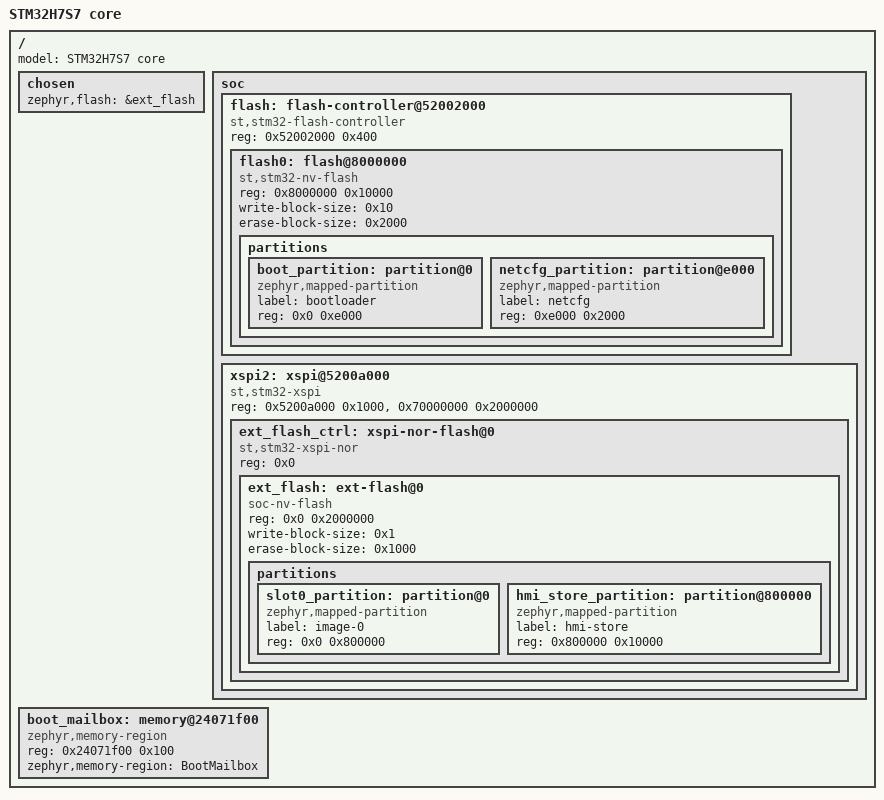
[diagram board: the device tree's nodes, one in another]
/dts-v1/;

/ {
	#address-cells = < 0x1 >;
	#size-cells = < 0x1 >;
	model = "STM32H7S7 core";
	chosen {
		zephyr,flash = &ext_flash;
	};
	soc {
		#address-cells = < 0x1 >;
		#size-cells = < 0x1 >;
		ranges;
		flash: flash-controller@52002000 {
			compatible = "st,stm32-flash-controller", "st,stm32h7rs-flash-controller";
			reg = < 0x52002000 0x400 >;
			#address-cells = < 0x1 >;
			#size-cells = < 0x1 >;
			flash0: flash@8000000 {
				compatible = "st,stm32-nv-flash", "soc-nv-flash";
				reg = < 0x8000000 0x10000 >;
				write-block-size = < 0x10 >;
				erase-block-size = < 0x2000 >;
				partitions {
					#address-cells = < 0x1 >;
					#size-cells = < 0x1 >;
					ranges;
					boot_partition: partition@0 {
						compatible = "zephyr,mapped-partition";
						label = "bootloader";
						reg = < 0x0 0xe000 >;
					};
					netcfg_partition: partition@e000 {
						compatible = "zephyr,mapped-partition";
						label = "netcfg";
						reg = < 0xe000 0x2000 >;
					};
				};
			};
		};
		xspi2: xspi@5200a000 {
			compatible = "st,stm32-xspi";
			reg = < 0x5200a000 0x1000 >, < 0x70000000 0x2000000 >;
			#address-cells = < 0x1 >;
			#size-cells = < 0x0 >;
			ext_flash_ctrl: xspi-nor-flash@0 {
				compatible = "st,stm32-xspi-nor";
				reg = < 0x0 >;
				#address-cells = < 0x1 >;
				#size-cells = < 0x1 >;
				ranges = < 0x0 0x70000000 0x2000000 >;
				ext_flash: ext-flash@0 {
					compatible = "soc-nv-flash";
					reg = < 0x0 0x2000000 >;
					write-block-size = < 0x1 >;
					erase-block-size = < 0x1000 >;
					#address-cells = < 0x1 >;
					#size-cells = < 0x1 >;
					ranges;
					partitions {
						#address-cells = < 0x1 >;
						#size-cells = < 0x1 >;
						ranges;
						slot0_partition: partition@0 {
							compatible = "zephyr,mapped-partition";
							label = "image-0";
							reg = < 0x0 0x800000 >;
						};
						hmi_store_partition: partition@800000 {
							compatible = "zephyr,mapped-partition";
							label = "hmi-store";
							reg = < 0x800000 0x10000 >;
						};
					};
				};
			};
		};
	};
	boot_mailbox: memory@24071f00 {
		compatible = "zephyr,memory-region", "mmio-sram";
		reg = < 0x24071f00 0x100 >;
		zephyr,memory-region = "BootMailbox";
		status = "okay";
	};
};
